AUTOSAR XML (schema 4-3-0)
package /ComponentTypes
  swc implementation YDF_SetPowerOffDriver_Implementation: behavior=YDF_SetPowerOffDriver_InternalBehavior
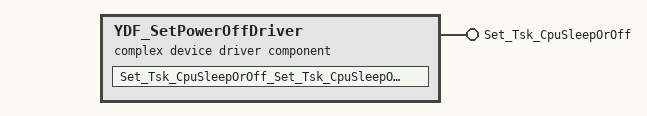
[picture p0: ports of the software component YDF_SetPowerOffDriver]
  complex device driver sw component type YDF_SetPowerOffDriver
    provide port Set_Tsk_CpuSleepOrOff: server-com-spec{operation=Set_Tsk_CpuSleepOrOff, queue-length=1}, provided-interface=Set_Tsk_CpuSleepOrOff
    behavior YDF_SetPowerOffDriver_InternalBehavior
      operation invoked event OIT_Set_Tsk_CpuSleepOrOff_Set_Tsk_CpuSleepOrOff_Set_Tsk_CpuSleepOrOff_Set_Tsk_CpuSleepOrOff: start-on-event=Set_Tsk_CpuSleepOrOff_Set_Tsk_CpuSleepOrOff, operation=Set_Tsk_CpuSleepOrOff.Set_Tsk_CpuSleepOrOff
      runnable Set_Tsk_CpuSleepOrOff_Set_Tsk_CpuSleepOrOff
